# TC37XPD register map
Vendor: Infineon; Series: ATVMC; File version: 100
CPU: other r0p0, little endian, MPU, FPU, vendor SysTick, 4 interrupt priority bits
Registers are 32-bit, read-write, reset 0x0 unless marked. A register's access mark holds for its fields unless they carry their own. Offsets are from the block's base; [hi:lo] are bit positions; lines under a group give offsets from that group; {n}, {i} and the like mark numbered series.

## GTM (part 6 of 13)
Base 0xF0100000
0x28000 DPLL group
  0xB4 INC_CNT2 — DPLL Counter for Pulses for TBU TS2 to be Sent in Automatic End Mode resetvalue={Application Reset:0x0}
    [23:0] INC_CNT2 — Actual number of pulses to be still sent out at the current increment until the next active input signal in automatic end mode. Automatic addition of the number of demanded pulses MLS2 when getting an active TRIGGER STATE input in normal or emergency mode respectively when SGE2 1 writeable only for test purposes when DEN 0 In the case of a change of the direction the wrong number of pulses are corrected twice Add the difference between NMB S and INC CNT2 twice to INC CNT2 before sending out the correction pulses. This value can only be written when the DPLL is disabled.
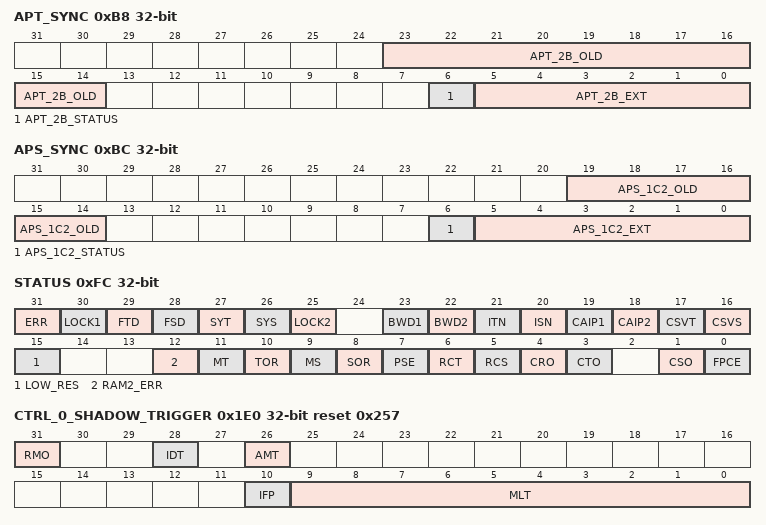
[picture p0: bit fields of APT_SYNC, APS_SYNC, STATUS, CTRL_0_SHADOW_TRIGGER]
  0xB8 APT_SYNC — DPLL Old RAM Pointer and Offset Value for TRIGGER resetvalue={Application Reset:0x0}
    [23:14] APT_2B_OLD — Address pointer TRIGGER for RAM region 2b at synchronization time. This value is set by the current APT 2B value when the synchronization takes place for the first active TRIGGER event after writing APT 2C but before adding the offset value APT 2B EXT that means when APT 2B STATUS 1 . Address pointer APT 2B value at the moment of synchronization before the offset value is added that means the pointer with this value points to the last value before the additional inserted gap.
    [6] APT_2B_STATUS — Address pointer 2b status. Set by CPU before the synchronization is performed. The value is cleared when the APT 2B OLD value is written.
    [5:0] APT_2B_EXT — Address pointer 2b extension. This offset value determines by which value the APT 2B is changed at the synchronization time set by CPU before the synchronization is performed. This offset value is the number of virtual increments to be inserted in the TSF for an imminent intended synchronization the CPU sets its value dependent on the gaps until the synchronization time taking into account the considered NUTE value to be set and including the next future increment when SYN T OLD is still 1 . When the synchronization takes place this value is to be added to the APT 2B address pointer for forward direction DIR1 0 and the APT 2B STATUS bit is cleared after it. For backward direction subtract APT 2B EXT accordingly. This correction is done after updating the RAM TSF with the last TS T value. When the synchronization is intended and the NUTE value is to be set to FULL SCALE after it the APT 2B EXT value must be set to 2 SYN NT in order to be able to fill all gaps in the extended TSF T with the corresponding values by the CPU. When still not all values for FULL SCALE are available the APT 2B EXT value considers only a share according to the corresponding NUTE value to be set after the synchronization.
  0xBC APS_SYNC — DPLL Old RAM Pointer and Offset Value for STATE resetvalue={Application Reset:0x0}
    [19:14] APS_1C2_OLD — Address pointer STATE for RAM region 1c2 at synchronization time. This value is set by the current APS 1C2 value when the synchronization takes place for the first active STATE event after writing APS 1C3 but before adding the offset value APS 1C2 EXT that means when APS 1C2 STATUS 1 . Address pointer APS 1C2 value at the moment of synchronization before the offset value is added that means the pointer with this value points to the last value before the additional inserted gap.
    [6] APS_1C2_STATUS — Address pointer 1c2 status. Set by CPU before the synchronization is performed. The value is cleared automatically when the APS 1C2 OLD value is written.
    [5:0] APS_1C2_EXT — Address pointer 1c2 extension. This offset value determines by which value the APS 1C2 is changed at the synchronization time set by CPU before the synchronization is performed. This offset value is the number of virtual increments to be inserted in the TSF for an imminent intended synchronization the CPU sets its value dependent on the gaps until the synchronization time taking into account the considered NUSE value to be set and including the next future increment when SYN S OLD is still 1 . When the synchronization takes place this value is to be added to the APS 1C2 address pointer for forward direction DIR2 0 and the APT 1c2 status bit is cleared after it. For backward direction subtract APS 1C2 EXT accordingly. When the synchronization is intended and the NUSE value is to be set to FULL SCALE after it the APS 1C2 EXT value must be set to SYN NS for SYSF 1 or 2 SYN NS for SYSF 0 in order to be able to fill all gaps in the extended TSF S with the corresponding values by the CPU. When still not all values for FULL SCALE are available the APS 1C2 EXT value considers only a share according to the NUSE value to be set after the synchronization.
  0xC0 TBU_TS0_T — DPLL TBU TS0 Value at Last TRIGGER Event resetvalue={Application Reset:0x0}
    [23:0] TBU_TS0_T — Value of TBU TS0 at the last TRIGGER event. For each T valid the value of TBU TS0 is stored in this register the register is writeable only for test purposes when DEN 0. This value can only be written when the DPLL is disabled.
  0xC4 TBU_TS0_S — DPLL TBU TS0 Value at Last STATE Event resetvalue={Application Reset:0x0}
    [23:0] TBU_TS0_S — Value of TBU TS0 at the last STATE event. For each S VALID the value of TBU TS0 is stored in this register the register is writeable only for test purposes when DEN 0. This value can only be written when the DPLL is disabled.
  0xC8 ADD_IN_LD1 — DPLL Direct Load Input Value for SUB INC1 resetvalue={Application Reset:0x0}
    [23:0] ADD_IN_LD1 — Input value for SUB INC1 generation. Given by CPU. This value can be used in normal und emergency mode SMC 0 as well as for SMC 1. For DLM1 1 The value is loaded by the CPU but used by the DPLL only for DLM1 1 see DPLL CTRL 1 register . When switching DLM1 to 1 the value in the register is used for the SUB INC1 generation beginning from the next active TRIGGER or STATE event respectively independently if new values are written by the CPU or not. When a new value is written the output frequency changes according to the given value beginning immediately from the moment of writing. Do not wait for performing step 10 in the state machine for ADD IN calculations. If the ADD IN LD1 value is zero all pulses are sent with the highest possible frequency. For DLM1 0 The value loaded by the CPU is stored directly in the internal add in register which is used to control the sub increment pulse generator directly see DPLL CTRL 1 register DLM1 0 . When a new ADD IN LD1 value is written the output frequency is immediately changed from the moment of writing. The ADD IN values calculated internally of the DPLL are written to the internal ADD IN register as well. In the moment when the internal calculation of the ADD IN values is writing the results into the internal ADD IN register of the pulse generator the internally calculated ADD IN values does always have higher priority compared to the values written via the ADD IN LD1 register. If the ADD IN LD1 value is zero all pulses are sent with the highest possible frequency.
  0xCC ADD_IN_LD2 — DPLL Direct Load Input Value for SUB INC2 resetvalue={Application Reset:0x0}
    [23:0] ADD_IN_LD2 — Input value for SUB INC2 generation. Given by CPU. This value can be used for SMC 1 while RMO 1. For DLM2 1 The value is loaded by the CPU but used by the DPLL only for DLM2 1 see DPLL CTRL 1 register . When switching DLM2 to 1 the value in the register is used for the SUB INC2 generation beginning from the next STATE event respectively independently if new values are written by the CPU or not. When a new value is written the output frequency changes according to the given value beginning immediately from the moment of writing. Do not wait for performing step 30 in the state machine for ADD IN calculations. If the ADD IN LD2 value is zero all pulses are sent with the highest possible frequency. For DLM2 0 The value loaded by the CPU is stored directly in the internal add in register which is used to control the sub increment pulse generator directly see DPLL CTRL 1 register DLM2 0 . When a new ADD IN LD2 value is written the output frequency is immediately changed from the moment of writing. The ADD IN values calculated internally of the DPLL are written to the internal ADD IN register as well. In the moment when the internal calculation of the ADD IN values is writing the results into the internal ADD IN register of the pulse generator the internally calculated ADD IN values does always have higher priority compared to the values written via the ADD IN LD2 register. If the ADD IN LD2 value is zero all pulses are sent with the highest possible frequency.
  0xFC STATUS access per field — DPLL Status Register resetvalue={Application Reset:0x0}
    [31] ERR ro — Error during configuration or operation resulting in unexpected values
    [30] LOCK1 ro — DPLL Lock status concerning SUB INC1. LOCK1 is set in normal mode for RMO SMC 0 LCD 0 Bit is set for an active TRIGGER event when SYT is set and the number of events between two gaps is as expected by the profile NT values in the ADT T i field or when SYN NT 0 and SYT 1. in normal mode for RMO SMC 0 LCD 1 Bit is set for an active TRIGGER event when SYT is set and the number of events between two increments without missing TRIGGER no gap is as expected by the profile NT values in the ADT T i field in emergency mode for RMO 1 and SMC 0 Bit is set for an active STATE event when SYS is set and the received events are in correspondence to the profile NS values in the ADT S i field for at least two four in case of direction change expected missing STATE events or when SYN NS 0. for SMC 1 Bit is set for an active TRIGGER even when SYT is set and SYN NT 0 or when SYT is set and the profile stored in the ADT T i field matches once between two gaps. LOCK1 is reset for RMO SMC 0 when a corresponding missing TRIGGER event occurs while SYN T 1. This does mean an unexpected missing TRIGGER. when the corresponding input signal TRIGGER is out of locking range TLR when a corresponding direction change is detected for RMO 1 and SMC 0 when a corresponding missing STATE event occurs while SYN S 1. This does mean an unexpected missing STATE. when the corresponding input signal STATE is out of locking range TLR for SMC 1 when a corresponding missing TRIGGER event occurs while SYN T 1. This does mean an unexpected missing TRIGGER. when the corresponding input signal TRIGGER is out of locking range TLR when a corresponding direction change is detected
    [29] FTD ro — First TRIGGER detected. No change of FTD for switching from normal to emergency mode or vice versa.
    [28] FSD ro — First STATE detected. No change of FSD for switching from normal to emergency mode or vice versa.
    [27] SYT ro — Synchronization condition of TRIGGER fixed. This bit is set when the CPU writes to the APT 2C address pointer.
    [26] SYS ro — Synchronization condition of STATE fixed. This bit is set when the CPU writes to the APS 1C3 address pointer.
    [25] LOCK2 ro — DPLL Lock status concerning SUB INC2. Locking of SUB INC2 appears for RMO SMC 1 Bit is set when SYS is set and the number of events between two missing STATE s is as expected by the SYN S values. LOCK2 is set for SMC RMO 1 for an active STATE event when SYS is set and SYN NS 0or when SYS is set and the profile stored in the ADT Si field matches once between two gaps. LOCK2 is reset for SMC RMO 1 when a missing STATE event occurs while SYN S 1. This does mean an unexpected missing STATE. when the corresponding input signal STATE is out of locking range SLR
    [23] BWD1 ro — Backwards drive of SUB INC1
    [22] BWD2 ro — Backwards drive of SUB INC2
    [21] ITN ro — Increment number of TRIGGER is not plausible. Bit is set when the number of TRIGGERS is different to profile.
    [20] ISN ro — Increment number of STATE is not plausible
    [19] CAIP1 ro — Calculation of lower half actionsin progress
    [18] CAIP2 ro — Calculation of upper half actions in progress
    [17] CSVT ro — Current signal value TRIGGER
    [16] CSVS ro — Current signal value STATE
    [15] LOW_RES ro — Low resolution of TBU TS0 is used for DPLL input. This value reflects the input signal LOW RES.
    [12] RAM2_ERR rw — DPLL internal access to not configured RAM2 memory space
    [11] MT rw — Missing TRIGGER detected according to TOV
    [10] TOR rw — TRIGGER out of range. The TOR bit is set when the time to the next active TRIGGER slope exceeds the value of the last nominal TRIGGER duration multiplied with the value of the TLR register see CROSSREFERENCE and is reset when at the current or last active input event a direction change was detected. The SYT bit is not influenced by setting the TOR bit.
    [9] MS rw — Missing STATE detected according to SOV
    [8] SOR rw — STATE out of range. The SOR bit is set when the time to the next active STATE slope exceeds the value of the last nominal STATE duration multiplied with the value of the SLR register see CROSSREFERENCE and is reset when at the current or last active input event a direction change was detected. The SYS bit is not influenced by setting the SOR bit.
    [7] PSE ro — Prediction space configuration error
    [6] RCT ro — Resolution conflict TRIGGER
    [5] RCS ro — Resolution conflict STATE
    [4] CRO rw — Calculated Reciprocal value overflow. Bit is set when the calculation of RDT T ACT or RDT S ACT leads to an overflow. An overflow in calculation of reciprocal values can occur when the condition of Note 3 to the DPLL CTRL 0 register is violated see CROSSREFERENCE . Such an overflow can occur according to the calculations in equations DPLL 1c or DPLL 6c . The overflow is detected when after the calculation and shifting left 32 bits at least one of the bits 31 to 24 is not zero. In that case the corresponding register is set to 0xFFFFFF.
    [3] CTO rw — Calculated TRIGGER duration overflow. Bit is set when equations DPLL 5a or DPLL 5b lead to an overflow. When one of the above bits is set the corresponding register contains the maximum value 0xFFFFFF.
    [1] CSO rw — Calculated STATE duration overflow. Bit is set when equations DPLL 10a or DPLL 10b lead to an overflow.
    [0] FPCE rw — Fast pulse correction error
  {0x100+4j} DPLL_ID_PMTR_z[{j}] (j=0..31) reset 0x1FE — DPLL ID Information for Input Signal PMT 0 Register resetvalue={Application Reset:0x1FE}
    [8:0] ID_PMTR_X — ID information to the input signal PMTR z from the ARU. This value can only be written when the action z is disabled by the correspondent bit AENz 0 of the registers DPLL CTRL 2 ...5 respectively or when the DPLL is disabled DEN 0 .
  0x1E0 CTRL_0_SHADOW_TRIGGER ro reset 0x257 — DPLL Control 0 Shadow Trigger Register resetvalue={Application Reset:0x257}
    [31] RMO — Reference mode. CROSSREFERENCE Selection of the relevant the input signal for generation of SUB INC1.
    [28] IDT — Input delay TRIGGER. CROSSREFERENCE Use of input delay information transmitted in FT part of the TRIGGER signal.
    [26] AMT — Adapt mode TRIGGER. CROSSREFERENCE Use of adaptation information of TRIGGER.
    [10] IFP — Input filter position. CROSSREFERENCE Value contains position or time related information.
    [9:0] MLT — Multiplier for TRIGGER. Only the values characterized by 1 are stored for an active TRIGGER slope. All other values remain 0. When DEN 0 the relevant bit values of the original register DPLL CTRL 0 are transferred without any input event at the next system clock. This results in the above reset value. MLT 1 is number of SUB INC1 pulses between two TRIGGER events in normal mode 1 8230 1024 .
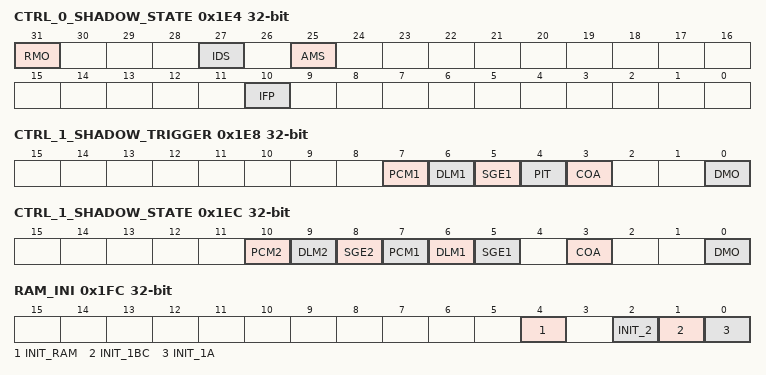
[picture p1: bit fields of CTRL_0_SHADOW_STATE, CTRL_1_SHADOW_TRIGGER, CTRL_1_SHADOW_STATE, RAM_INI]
  0x1E4 CTRL_0_SHADOW_STATE ro — DPLL Control 0 Shadow STATE Register resetvalue={Application Reset:0x0}
    [31] RMO — Reference mode. CROSSREFERENCE Selection of the relevant the input signal for generation of SUB INC1.
    [27] IDS — Input delay STATE. CROSSREFERENCE Use of input delay information transmitted in FT part of the STATE signal.
    [25] AMS — Adapt mode STATE. CROSSREFERENCE Use of adaptation information of STATE.
    [10] IFP — Input filter position. Only the values characterized by 1 are stored for an active STATE slope. All other values remain 0. When DEN 0 the relevant bit values of the original register DPLL CTRL 0 are transferred without any input event at the next system clock. Value contains position or time related information.
  0x1E8 CTRL_1_SHADOW_TRIGGER ro — DPLL Control 1 Shadow TRIGGER Register resetvalue={Application Reset:0x0}
    [7] PCM1 — Pulse Correction Mode for SUB INC1 generation. CROSSREFERENCE
    [6] DLM1 — Direct Load Mode for SUB INC1 generation. CROSSREFERENCE
    [5] SGE1 — SUB INC1 generator enable. CROSSREFERENCE
    [4] PIT — Plausibility value PVT to next valid TRIGGER is time related. CROSSREFERENCE
    [3] COA — Correction strategy in automatic end mode DMO 0 . CROSSREFERENCE
    [0] DMO — DPLL mode select. Only the values characterized by 1 are stored for an active TRIGGER slope. All other values remain 0. When DEN 0 the relevant bit values of the original register DPLL CTRL 1 are transferred without any input event at the next system clock.
  0x1EC CTRL_1_SHADOW_STATE ro — DPLL Control 1 Shadow STATE Register resetvalue={Application Reset:0x0}
    [10] PCM2 — Pulse Correction Mode for SUB INC2 generation. CROSSREFERENCE
    [9] DLM2 — Direct Load Mode for SUB INC2 generation. CROSSREFERENCE
    [8] SGE2 — SUB INC2 generator enable. CROSSREFERENCE
    [7] PCM1 — Pulse Correction Mode for SUB INC1 generation. CROSSREFERENCE
    [6] DLM1 — Direct Load Mode for SUB INC1 generation. CROSSREFERENCE
    [5] SGE1 — SUB INC1 generator enable. CROSSREFERENCE
    [3] COA — Correction strategy in automatic end mode DMO 0 . CROSSREFERENCE
    [0] DMO — DPLL mode select. Only the values characterized by 1 are stored for an active STATE slope. All other values remain 0. When DEN 0 the relevant bit values of the original register DPLL CTRL 1 are transferred without any input event at the next system clock.
  0x1FC RAM_INI access per field — DPLL RAM Initialization Register resetvalue={Application Reset:0x0}
    [4] INIT_RAM rw — RAM regions 1a 1b and 2 are to be initialized. Setting the INIT RAM bit results only in a RAM reset when the DPLL is not enabled DEN 0 . Depending on the vendor configuration the connected RAM regions are initialized to zero in the case of a module HW reset or for setting the RST bit in the GTM RST register. In the case of no RAM initialization it must be ensured that all relevant parameters are configured correctly. Otherwise there is no guarantee to get a predictable behavior.
    [2] INIT_2 ro — RAM region 2 initialization in progress. Coding see bit 0.
    [1] INIT_1BC ro — RAM region 1b and 1c initialization in progress. Coding see bit 0.
    [0] INIT_1A ro — RAM region 1a initialization in progress
  {0x200+4j} DPLL_PSAi[{j}] (j=0..31) reset not defined — DPLL ACTION 0 Position Value Request resetvalue={PowerOn Reset:0x0,DPLL_RAM_INI.INIT_1A:0x0}
    [23:0] PSA — Position information of a desired action i. This value can only be written when the DPLL is disabled. The PSA values for actions 24...31 are not available for all devices but depends on specific product configuration.
  {0x280+4j} DPLL_DLAi[{j}] (j=0..31) reset not defined — DPLL ACTION 0 Time to React before PSAi resetvalue={PowerOn Reset:0x0,DPLL_RAM_INI.INIT_1A:0x0}
    [23:0] DLA — Time to react before the corresponding position value of a desired action i is reached. In the case of LOW RES 1 see CROSSREFERENCE this delay value must be also given as low resolution value. This value can only be written when the DPLL is disabled.
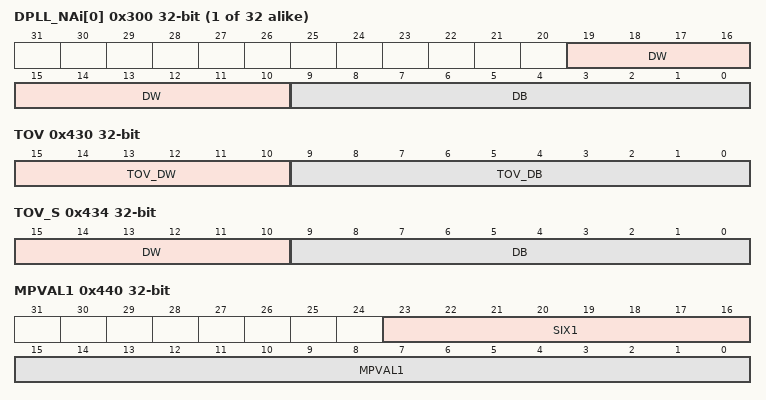
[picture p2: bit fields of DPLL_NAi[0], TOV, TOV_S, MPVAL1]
  {0x300+4j} DPLL_NAi[{j}] (j=0..31) reset not defined — DPLL Calculated Number of TRIGGER STATE Increments to ACTION 0 resetvalue={PowerOn Reset:0x0,DPLL_RAM_INI.INIT_1A:0x0}
    [19:10] DW — Number of events to Action i integer part . Use the maximum value for NA DW 0x3FF in the case of a calculated value which exceeds the represent able value. This value can only be written when the DPLL is disabled.
    [9:0] DB — Number of events to Action i fractional part . The NA values for actions 24...31 are only available for device 4 or 5. This value can only be written when the DPLL is disabled.
  {0x380+4j} DPLL_DTAi[{j}] (j=0..31) reset not defined — DPLL Calculated Relative TIME to ACTION 0 resetvalue={PowerOn Reset:0x0,DPLL_RAM_INI.INIT_1A:0x0}
    [23:0] DTA — Calculated relative time to ACTION i. This value can only be written when the DPLL is disabled. The DTA value is a positive integer value. When calculations using equations DPLL 12 or DPLL 14 result in a negative value it is replaced by zero.
  0x400 TS_T reset not defined — DPLL Actual TRIGGER Time Stamp Value resetvalue={PowerOn Reset:0x0,DPLL_RAM_INI.INIT_1BC:0x0}
    [23:0] TRIGGER_TS — Time stamp value of the last active TRIGGER input. Measured TRIGGER time stamp. The LSB address is determined using the SWON T value in the OSW register see CROSSREFERENCE .
  0x404 TS_T_OLD reset not defined — DPLL Previous TRIGGER Time Stamp Value resetvalue={PowerOn Reset:0x0,DPLL_RAM_INI.INIT_1BC:0x0}
    [23:0] TRIGGER_TS_OLD — Time stamp value of the last but one active TRIGGER input. Previous measured TRIGGER time stamp. The LSB address is determined using the SWON T value in the OSW register see CROSSREFERENCE .
  0x408 FTV_T reset not defined — DPLL Actual TRIGGER Filter Value resetvalue={PowerOn Reset:0x0,DPLL_RAM_INI.INIT_1BC:0x0}
    [23:0] TRIGGER_FT — Filter value of the last active TRIGGER input. Transmitted filter value. The LSB address is determined using the SWON T value in the OSW register see CROSSREFERENCE .
  0x410 TS_S reset not defined — DPLL Actual STATE Time Stamp resetvalue={PowerOn Reset:0x0,DPLL_RAM_INI.INIT_1BC:0x0}
    [23:0] STATE_TS — Time stamp value of the last active STATE input. The LSB address is determined using the SWON S value in the OSW register see CROSSREFERENCE .
  0x414 TS_S_OLD reset not defined — DPLL Previous STATE Time Stamp resetvalue={PowerOn Reset:0x0,DPLL_RAM_INI.INIT_1BC:0x0}
    [23:0] STATE_TS_OLD — Time stamp value of the last active STATE input. The LSB address is determined using the SWON S value in the OSW register see CROSSREFERENCE .
  0x418 FTV_S reset not defined — DPLL Actual STATE Filter Value resetvalue={PowerOn Reset:0x0,DPLL_RAM_INI.INIT_1BC:0x0}
    [23:0] STATE_FT — Filter value of the last active STATE input. transmitted filter value The LSB address is determined using the SWON S value in the OSW register see CROSSREFERENCE .
  0x420 THMI reset not defined — DPLL TRIGGER Hold Time Minimum Value resetvalue={PowerOn Reset:0x0,DPLL_RAM_INI.INIT_1BC:0x0}
    [15:0] THMI — Minimal time between active and inactive TRIGGER slope uint16 . The time value corresponds to the time stamp clock counts this does mean the clock selected for the TBU CH0 BASE see TBU CH0 CTRL register set min. value generate the TINI interrupt in the case of a violation for THMI gt 0. Typical retention time values after an active slope can be e.g. between 45 181 s forwards and 90 181 s backwards . When THMI is zero consider always a THMI violation forwards .
  0x424 THMA reset not defined — DPLL TRIGGER Hold Time Maximum Value resetvalue={PowerOn Reset:0x0,DPLL_RAM_INI.INIT_1BC:0x0}
    [15:0] THMA — Maximal time between active and inactive TRIGGER slope uint16 . The time value corresponds to the time stamp clock counts This does mean the clock selected for the TBU CH0 BASE see TBU CH0 CTRL register Max. value to be set generate the TAX interrupt in the case of a violation for THMA gt 0.
  0x428 THVAL reset not defined — DPLL Measured TRIGGER Hold Time Value resetvalue={PowerOn Reset:0x0,DPLL_RAM_INI.INIT_1BC:0x0}
    [23:0] THVAL — Measured time from the last active slope to the next inactive TRIGGER slope in time stamp clock counts this does mean the clock selected for the TBU CH0 BASE uint16 . The measured value considers all input slope filter delays. From the received input the corresponding filter delays are subtracted before the time stamp difference of active and inactive slope is calculated.
  0x430 TOV reset not defined — DPLL Time Out Value of Active TRIGGER Slope resetvalue={PowerOn Reset:0x0,DPLL_RAM_INI.INIT_1BC:0x0}
    [15:10] TOV_DW — Decision value integer part for missing TRIGGER interrupt. TOV 15 0 is to be multiplied with the duration of the last increment and divided by 1024 in order to get the time out time value for a missing TRIGGER event. For the case of LOW RES 1 see DPLL STATUS register consider for the calculation of the time out value the following cases LOW RES 1 and DPLL CTRL 1 TS0 HRT 1 160 160 160 multiply the TBU TS0 value by 8 LOW RES 1 and DPLL CTRL 1 TS0 HRT 0 160 160 160 multiply the TBU TS0 value by 8 160 160 160 multiply the estimated time point value using TS T dt t ACT and 160 160 160 TOV by 8 LOW RES 0 and DPLL CTRL 1 TS0 HRT 0 160 160 160 use TBU TS0 and the estimated time point value unchanged.
    [9:0] TOV_DB — Decision value fractional part for missing TRIGGER interrupt
  0x434 TOV_S reset not defined — DPLL Time Out Value of Active STATE Slope resetvalue={PowerOn Reset:0x0,DPLL_RAM_INI.INIT_1BC:0x0}
    [15:10] DW — Decision value integer part for missing STATE interrupt. TOV S 15 0 is to be multiplied with the duration of the last increment and divided by 1024 in order to get the time out time value for a missing STATE event. For the case of LOW RES 1 see DPLL STATUS register consider for the calculation of the time out value the following cases LOW RES 1 and DPLL CTRL 1 TS0 HRS 1 160 160 160 multiply the TBU TS0 value by 8 LOW RES 1 and DPLL CTRL 1 TS0 HRS 0 160 160 160 multiply the TBU TS0 value by 8 160 160 160 multiply the estimated time point value using TS T dt s ACT and 160 160 160 SOV by 8 LOW RES 0 and DPLL CTRL 1 TS0 HRS 0 160 160 160 use TBU TS0 and the estimated time point value unchanged.
    [9:0] DB — Decision value fractional part for missing STATE interrupt
  0x438 ADD_IN_CAL1 reset not defined — DPLL Calculated ADD IN Value for SUB INC1 Generation resetvalue={PowerOn Reset:0x0,DPLL_RAM_INI.INIT_1BC:0x0}
    [23:0] ADD_IN_CAL1 — Calculated input value for SUB INC1 generation calculated by the DPLL. Calculated value. The update of the ADD IN value by the new calculated value ADD IN CAL1 is suppressed for one increment when an unexpected missing TRIGGER SMC 1 or RMO 0 or an unexpected STATE RMO 1 and SMC 0 is detected.
  0x43C ADD_IN_CAL2 reset not defined — DPLL Calculated ADD IN Value for SUB INC2 Generation resetvalue={PowerOn Reset:0x0,DPLL_RAM_INI.INIT_1BC:0x0}
    [23:0] ADD_IN_CAL2 — Input value for SUB INC2 generation calculated by the DPLL for SMC RMO 1. Calculated value. The update of the ADD IN value by the calculated value ADD IN CAL2 is suppressed for one increment when an unexpected missing STATE RMO SMC 1 is detected.
  0x440 MPVAL1 reset not defined — DPLL Missing Pulses to be Added or Subtracted Directly 1 resetvalue={PowerOn Reset:0x0,DPLL_RAM_INI.INIT_1BC:0x0}
    [23:16] SIX1 — Sign extension for MPVAL1. All bits must be written to either all zeros or all ones.
    [15:0] MPVAL1 — Missing pulses for direct correction of SUB INC1 pulses by the CPU sint16 . Used only for RMO 0 or SMC 1 for the case PCM1 1. Add MPVAL1 once to INC CNT1 and reset PCM1 after applying once.
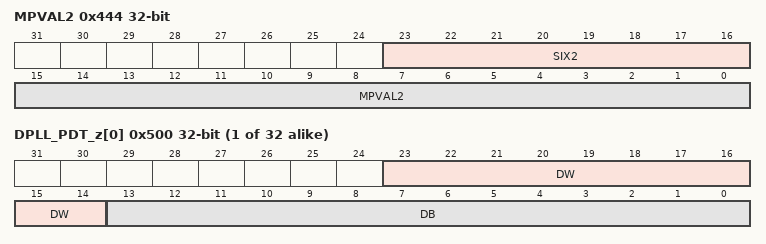
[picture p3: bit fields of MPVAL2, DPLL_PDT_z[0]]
  0x444 MPVAL2 reset not defined — DPLL Missing Pulses to be Added or Subtracted Directly 2 resetvalue={PowerOn Reset:0x0,DPLL_RAM_INI.INIT_1BC:0x0}
    [23:16] SIX2 — Sign extension for MPVAL2. All bits must be written to either all zeros or all ones.
    [15:0] MPVAL2 — Missing pulses for direct correction of SUB INC2 pulses by the CPU sint16 . Used only for SMC RMO 1 for the case PCM2 1. Add MPVAL2 once to INC CNT2 and reset PCM2 after applying once. Do not provide negative values which exceed the amount of MLS2 when considered negative PD S values the sum of both should not exceed the amount of MLS2.
  0x448 NMB_T_TAR reset not defined — DPLL Target Number of Pulses to be Sent in Normal Mode resetvalue={PowerOn Reset:0x0,DPLL_RAM_INI.INIT_1BC:0x0}
    [15:0] NMB_T_TAR — Target Number of pulses for TRIGGER. Calculated number of pulses in normal mode for the current TRIGGER increment without missing pulses. Calculated target pulse number. The LSB address is determined using the SWON T value in the OSW register see CROSSREFERENCE .
  0x44C NMB_T_TAR_OLD reset not defined — DPLL Last but One Target Number of Pulses to be Sent in Normal Mode resetvalue={PowerOn Reset:0x0,DPLL_RAM_INI.INIT_1BC:0x0}
    [15:0] NMB_T_TAR_OLD — Target Number of pulses for TRIGGER. Calculated number of pulses in normal mode for the current TRIGGER increment without missing pulses. Calculated target pulse number. The LSB address is determined using the SWON T value in the OSW register see CROSSREFERENCE .
  0x450 NMB_S_TAR reset not defined — DPLL Target Number of Pulses to be Sent in Emergency Mode resetvalue={PowerOn Reset:0x0,DPLL_RAM_INI.INIT_1BC:0x0}
    [19:0] NMB_S_TAR — Target Number of pulses for STATE. Calculated number of pulses in emergency mode for the current STATE increment without missing pulses. Calculated target pulse number. The LSB address is determined using the SWON S value in the OSW register see CROSSREFERENCE .
  0x454 NMB_S_TAR_OLD reset not defined — DPLL Last but One Target Number of Pulses to be Sent in Emergency Mode resetvalue={PowerOn Reset:0x0,DPLL_RAM_INI.INIT_1BC:0x0}
    [19:0] NMB_S_TAR_OLD — Target Number of pulses for STATE. Calculated number of pulses in emergency mode for the current STATE increment without missing pulses. Calculated target pulse number. The LSB address is determined using the SWON S value in the OSW register see CROSSREFERENCE .
  0x460 RCDT_TX reset not defined — DPLL Reciprocal Value of the Expected Increment Duration of TRIGGER resetvalue={PowerOn Reset:0x0,DPLL_RAM_INI.INIT_1BC:0x0}
    [23:0] RCDT_TX — Reciprocal value of expected increment duration 2 32 while only the lower 24 bits are used. Calculated value when an overflow occurs in the calculation the value is set to 0xFFFFFF.
  0x464 RCDT_SX reset not defined — DPLL Reciprocal Value of the Expected Increment Duration of STATE resetvalue={PowerOn Reset:0x0,DPLL_RAM_INI.INIT_1BC:0x0}
    [23:0] RCDT_SX — Reciprocal value of expected increment duration 2 32 while only the lower 24 bits are used. Calculated value when an overflow occurs in the calculation the value is set to 0xFFFFFF.
  0x468 RCDT_TX_NOM reset not defined — DPLL Reciprocal Value of the Expected Nominal Increment Duration of TRIGGER resetvalue={PowerOn Reset:0x0,DPLL_RAM_INI.INIT_1BC:0x0}
    [23:0] RCDT_TX_NOM — Reciprocal value of nominal increment duration 2 32 while only the lower 24 bits are used. Calculated value when an overflow occurs in the calculation the value is set to 0xFFFFFF.
  0x46C RCDT_SX_NOM reset not defined — DPLL Reciprocal Value of the Expected Nominal Increment Duration of STATE resetvalue={PowerOn Reset:0x0,DPLL_RAM_INI.INIT_1BC:0x0}
    [23:0] RCDT_SX_NOM — Reciprocal value of nominal increment duration 2 32 while only the lower 24 bits are used. Calculated value when an overflow occurs in the calculation the value is set to 0xFFFFFF.
  0x470 RDT_T_ACT reset not defined — DPLL Reciprocal Value of the Last Increment of TRIGGER resetvalue={PowerOn Reset:0x0,DPLL_RAM_INI.INIT_1BC:0x0}
    [23:0] RDT_T_ACT — Reciprocal value of last TRIGGER increment 2 32 only the lower 24 bits are used. The LSB is rounded up when the next truncated bit is 1. Calculated value when an overflow occurs in the calculation the value is set to 0xFFFFFF and the CRO bit in the DPLL STATUS register is set see CROSSREFERENCE .
  0x474 RDT_S_ACT reset not defined — DPLL Reciprocal Value of the Last Increment of STATE resetvalue={PowerOn Reset:0x0,DPLL_RAM_INI.INIT_1BC:0x0}
    [23:0] RDT_S_ACT — Reciprocal value of last STATE increment 2 32 only the lower 24 bits are used. The LSB is rounded up when the next truncated bit is 1. Calculated value when an overflow occurs in the calculation the value is set to 0xFFFFFF and the CRO bit in the DPLL STATUS register is set see CROSSREFERENCE .
  0x478 DT_T_ACT reset not defined — DPLL Duration of the Last TRIGGER Increment resetvalue={PowerOn Reset:0x0,DPLL_RAM_INI.INIT_1BC:0x0}
    [23:0] DT_T_ACT — Calculated duration of the last TRIGGER increment. Calculated duration of the last increment Value will be written into the corresponding RAM field when all calculations for the considered increment are done and APT is valid.
  0x47C DT_S_ACT reset not defined — DPLL Duration of the Last STATE Increment resetvalue={PowerOn Reset:0x0,DPLL_RAM_INI.INIT_1BC:0x0}
    [23:0] DT_S_ACT — Calculated duration of the last STATE increment. Calculated increment duration. Value will be written into the corresponding RAM field when all calculations for the considered increment are done and APS is valid.
  0x480 EDT_T reset not defined — DPLL Difference of Prediction to Actual Value of the Last TRIGGER Increment resetvalue={PowerOn Reset:0x0,DPLL_RAM_INI.INIT_1BC:0x0}
    [23:0] EDT_T — Signed difference between actual value and a simple prediction of the last TRIGGER increment sint24. Calculated error value.
  0x484 MEDT_T reset not defined — DPLL Weighted Difference of Prediction Errors of TRIGGER resetvalue={PowerOn Reset:0x0,DPLL_RAM_INI.INIT_1BC:0x0}
    [23:0] MEDT_T — Signed middle weighted difference between actual value and prediction of the last TRIGGER increments sint24. Only calculated for SYT 1. Calculated medium error value see CROSSREFERENCE . The value is calculated only after synchronization SYT 1 and the update is suppressed for one increment when an unexpected missing TRIGGER is detected.
  0x488 EDT_S reset not defined — DPLL Difference of Prediction to Actual Value of the Last STATE Increment resetvalue={PowerOn Reset:0x0,DPLL_RAM_INI.INIT_1BC:0x0}
    [23:0] EDT_S — Signed difference between actual value and prediction of the last STATE increment sint24. Calculated error value see CROSSREFERENCE .
  0x48C MEDT_S reset not defined — DPLL Weighted Difference of Prediction Errors of STATE resetvalue={PowerOn Reset:0x0,DPLL_RAM_INI.INIT_1BC:0x0}
    [23:0] MEDT_S — Signed middle weighted difference between actual value and prediction of the last STATE increments sint24 only calculated for SYS 1. Calculated medium error value see CROSSREFERENCE . The value is calculated only after synchronization SYS 1 and the update is suppressed for one increment when an unexpected missing STATE is detected.
  0x490 CDT_TX reset not defined — DPLL Prediction of the Actual TRIGGER Increment Duration resetvalue={PowerOn Reset:0x0,DPLL_RAM_INI.INIT_1BC:0x0}
    [23:0] CDT_TX — Calculated duration of the current TRIGGER increment. Calculated value.
  0x494 CDT_SX reset not defined — DPLL Prediction of the Actual STATE Increment Duration resetvalue={PowerOn Reset:0x0,DPLL_RAM_INI.INIT_1BC:0x0}
    [23:0] CDT_SX — Calculated duration of the current STATE increment. Calculated value.
  0x498 CDT_TX_NOM reset not defined — DPLL Prediction of the Nominal TRIGGER Increment Duration resetvalue={PowerOn Reset:0x0,DPLL_RAM_INI.INIT_1BC:0x0}
    [23:0] CDT_TX_NOM — Calculated duration of the current nominal TRIGGER event. Calculated value.
  0x49C CDT_SX_NOM reset not defined — DPLL Prediction of the Nominal STATE Increment Duration resetvalue={PowerOn Reset:0x0,DPLL_RAM_INI.INIT_1BC:0x0}
    [23:0] CDT_SX_NOM — Calculated duration of the current nominal STATE event. Calculated value.
  0x4A0 TLR reset not defined — DPLL TRIGGER Locking Range resetvalue={PowerOn Reset:0x0,DPLL_RAM_INI.INIT_1BC:0x0}
    [7:0] TLR — Value is to be multiplied with the last nominal TRIGGER duration in order to get the range for the next TRIGGER event without setting TOR in the DPLL STATUS register. Multiply value with the last nominal increment duration and check violation when TLR 0 don t perform the check.
  0x4A4 SLR reset not defined — DPLL STATE Locking Range resetvalue={PowerOn Reset:0x0,DPLL_RAM_INI.INIT_1BC:0x0}
    [7:0] SLR — Value is to be multiplied with the last nominal STATE duration in order to get the range for the next STATE event without setting SOR in the DPLL STATUS register. Multiply value with the last nominal increment duration and check violation when SLR 0 don t perform the check.
  {0x500+4j} DPLL_PDT_z[{j}] (j=0..31) reset not defined — DPLL Projected Increment Sum Relations for Action 0 resetvalue={PowerOn Reset:0x0,DPLL_RAM_INI.INIT_1BC:0x0}
    [23:14] DW — Integer part of relation between TRIGGER or STATE increments. Definition of relation values between TRIGGER or STATE increments PDT i according to Equations DPLL 11 or DPLL 13 i 0 31 . . The PDT z values for actions i 24...31 are not available for all devices. The PDT i values for actions i 24...31 are only available for device 4 or 5.
    [13:0] DB — Fractional part of relation between TRIGGER or STATE increments
  0x5C0 MLS1 reset not defined — DPLL Calculated Number of Sub Pulses between two Nominal STATE Events for SMC 0 resetvalue={PowerOn Reset:0x0,DPLL_RAM_INI.INIT_1BC:0x0}
    [17:0] MLS1 — Number of pulses between two STATE events. For SMC 0 the value of MLS1 is calculated once by the CPU for fixed values in the DPLL CTRL 0 register by the formula MLS1 MLT 1 TNU 1 SNU 1 and set accordingly. For SMC 1 the value of MLS1 represents the number of pulses between two nominal TRIGGER events to be set and updated by the CPU .
  0x5C4 MLS2 reset not defined — DPLL Calculated Number of Sub Pulses between two Nominal STATE Events for SMC 1 and RMO 1 resetvalue={PowerOn Reset:0x0,DPLL_RAM_INI.INIT_1BC:0x0}
    [17:0] MLS2 — Number of pulses between two STATE events to be set and updated by the CPU . Using adapt information and the missing STATE event information SYN S this value can be corrected for each increment automatically.
  0x5C8 CNT_NUM_1 reset not defined — DPLL Number of Sub Pulses of SUB INC1 in Continuous Mode resetvalue={PowerOn Reset:0x0,DPLL_RAM_INI.INIT_1BC:0x0}
    [23:0] CNT_NUM_1 — Counter for number of SUB INC1 pulses. Number of pulses in continuous mode for a nominal increment in normal and emergency mode for SUB INC1 given and updated by CPU only. Count value for continuous mode.
  0x5CC CNT_NUM_2 reset not defined — DPLL Number of Sub Pulses of SUB INC2 in Continuous Mode resetvalue={PowerOn Reset:0x0,DPLL_RAM_INI.INIT_1BC:0x0}
    [23:0] CNT_NUM_2 — Counter for number of SUB INC2 pulses. Number of pulses in continuous mode for a nominal increment in normal and emergency mode for SUB INC2 given and updated by CPU only. Count value for continuous mode.
